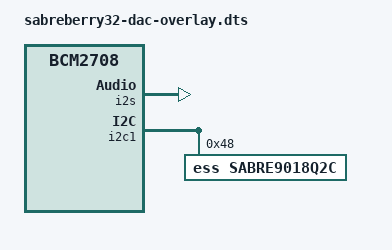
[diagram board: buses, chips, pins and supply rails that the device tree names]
// Definitions for SabreBerry32
/dts-v1/;
/plugin/;

/ {
	compatible = "brcm,bcm2708";

	fragment@0 {
		target = <&sound>;
		frag0: __overlay__ {
			compatible = "takazine,sabreberry32";
			i2s-controller = <&i2s>;
			status = "okay";
		};
	};

	fragment@1 {
		target = <&i2s>;
		__overlay__ {
			status = "okay";
		};
	};

	fragment@2 {
		target = <&i2c1>;
		__overlay__ {
			#address-cells = <1>;
			#size-cells = <0>;
			status = "okay";

			sabre9018q2c@48 {
				#sound-dai-cells = <0>;
				compatible = "ess,sabre9018q2c";
				reg = <0x48>;
				status = "okay";
			};
		};
	};

	__overrides__ {
		slave = <&frag0>,"takazine,slave?";
	};
};
